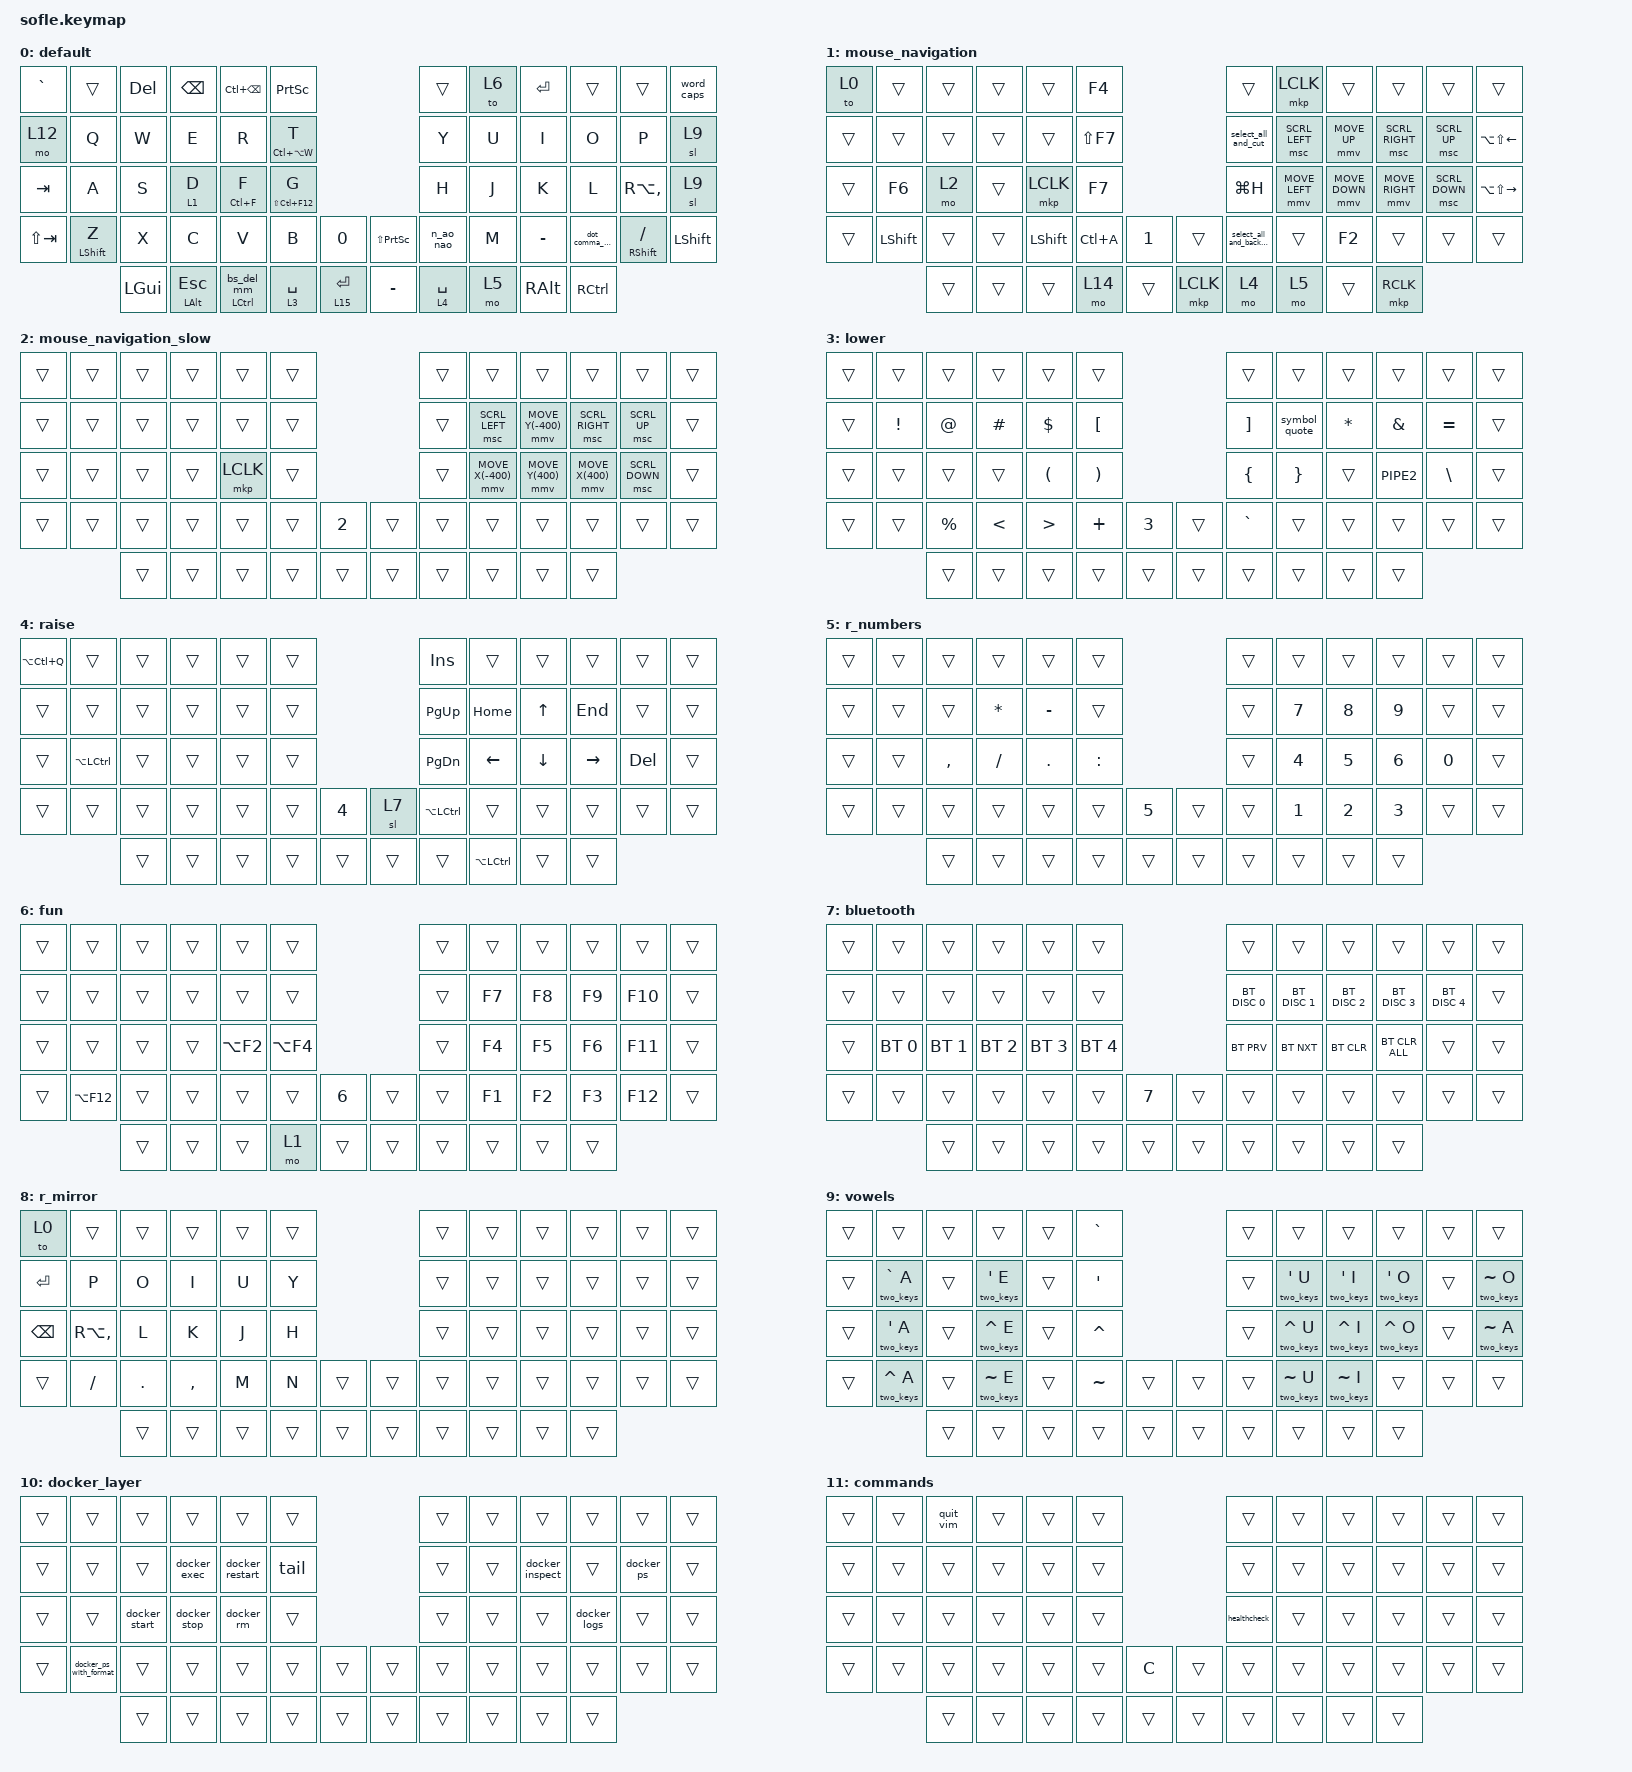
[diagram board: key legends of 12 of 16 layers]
/*
 * Copyright (c) 2020 The ZMK Contributors
 *
 * SPDX-License-Identifier: MIT
 */

#include <behaviors.dtsi>
#include <dt-bindings/zmk/bt.h>
#include <dt-bindings/zmk/keys.h>
#include <dt-bindings/zmk/pointing.h>

#define BASE 0
#define LOWER 1
#define RAISE 2
#define ADJUST 3
#define ZMK_POINTING_DEFAULT_MOVE_VAL 2000  // default: 600
#define ZMK_POINTING_DEFAULT_SCRL_VAL 20    // default: 10

/ {
    // Activate ADJUST layer by pressing raise and lower

    conditional_layers { compatible = "zmk,conditional-layers"; };

    combos {
        compatible = "zmk,combos";

        to_fun_layer {
            bindings = <&sl 6>;
            key-positions = <25 34>;
        };

        alt_x {
            bindings = <&kp LA(X)>;
            key-positions = <37 38>;
        };

        docker_layer {
            bindings = <&sl 10>;
            key-positions = <10 11>;
        };

        to_mirror_layer {
            bindings = <&to 8>;
            key-positions = <52 29>;
        };

        to_default_layer {
            bindings = <&to 0>;
            key-positions = <53 29>;
        };

        commands_layer {
            bindings = <&sl 11>;
            key-positions = <22 23>;
        };

        to_l_numbers {
            bindings = <&to 12>;
            key-positions = <0 1>;
        };

        to_mouse_layer_left {
            bindings = <&to 1>;
            key-positions = <55 30>;
        };

        to_wmctrl_layer {
            bindings = <&sl 13>;
            key-positions = <45 14>;
        };

        to_nav_layer {
            bindings = <&to 1>;
            key-positions = <25 48>;
        };

        colon {
            bindings = <&colon_scolon_mm>;
            key-positions = <31 19>;
        };

        comma {
            bindings = <&kp COMMA>;
            key-positions = <20 32>;
        };

        underscore {
            bindings = <&kp LS(UNDERSCORE)>;
            key-positions = <28 40>;
        };
    };

    macros {
        docker_exec: docker_exec {
            compatible = "zmk,behavior-macro";
            #binding-cells = <0>;
            bindings = <&kp D &kp O &kp C &kp K &kp E &kp R &kp SPACE &kp E &kp X &kp E &kp C &kp SPACE &kp MINUS &kp I &kp T &kp SPACE &kp SPACE &kp B &kp A &kp S &kp H &kp LC(LEFT_ARROW) &kp LEFT_ARROW>;
            label = "DOCKER_EXEC";
            wait-ms = <1>;
            tap-ms = <1>;
        };

        docker_logs: docker_logs {
            compatible = "zmk,behavior-macro";
            #binding-cells = <0>;
            bindings =
                <&kp D &kp O &kp C &kp K &kp E &kp R &kp SPACE &kp L &kp O &kp G &kp S &kp SPACE &kp MINUS &kp MINUS &kp T &kp A &kp I &kp L &kp SPACE &kp N1 &kp N0 &kp N0 &kp N0 &kp SPACE &kp MINUS &kp F &kp SPACE>,
                <&macro_press>;

            label = "DOCKER_LOGS";
            wait-ms = <1>;
            tap-ms = <1>;
        };

        docker_ps: docker_ps {
            compatible = "zmk,behavior-macro";
            #binding-cells = <0>;
            bindings = <&kp D &kp O &kp C &kp K &kp E &kp R &kp SPACE &kp P &kp S &kp SPACE &kp MINUS &kp A &kp SPACE &kp PIPE &kp SPACE &kp G &kp R &kp E &kp P &kp SPACE>;
            label = "DOCKER_PS";
            wait-ms = <1>;
            tap-ms = <1>;
        };

        docker_rm: docker_rm {
            compatible = "zmk,behavior-macro";
            #binding-cells = <0>;
            bindings = <&kp D &kp O &kp C &kp K &kp E &kp R &kp SPACE &kp R &kp M &kp SPACE &kp MINUS &kp F &kp SPACE>;
            label = "DOCKER_RM";
            wait-ms = <1>;
            tap-ms = <1>;
        };

        docker_start: docker_start {
            compatible = "zmk,behavior-macro";
            #binding-cells = <0>;
            bindings = <&kp D &kp O &kp C &kp K &kp E &kp R &kp SPACE &kp S &kp T &kp A &kp R &kp T &kp SPACE>;
            label = "DOCKER_START";
            wait-ms = <1>;
            tap-ms = <1>;
        };

        docker_stop: docker_stop {
            compatible = "zmk,behavior-macro";
            #binding-cells = <0>;
            bindings = <&kp D &kp O &kp C &kp K &kp E &kp R &kp SPACE &kp S &kp T &kp O &kp P &kp SPACE>;
            label = "DOCKER_STOP";
            wait-ms = <1>;
            tap-ms = <1>;
        };

        docker_inspect: docker_inspect {
            compatible = "zmk,behavior-macro";
            #binding-cells = <0>;
            bindings = <&kp D &kp O &kp C &kp K &kp E &kp R &kp SPACE &kp I &kp N &kp S &kp P &kp E &kp C &kp T &kp SPACE>;
            label = "DOCKER_INSPECT";
            wait-ms = <1>;
            tap-ms = <1>;
        };

        tail: tail {
            compatible = "zmk,behavior-macro";
            #binding-cells = <0>;
            bindings = <&kp T &kp A &kp I &kp L &kp SPACE &kp MINUS &kp F &kp SPACE &kp MINUS &kp N &kp SPACE &kp N1 &kp N0 &kp N0 &kp N0 &kp SPACE>;
            label = "TAIL";
            wait-ms = <1>;
            tap-ms = <1>;
        };

        docker_restart: docker_restart {
            compatible = "zmk,behavior-macro";
            #binding-cells = <0>;
            bindings = <&kp D &kp O &kp C &kp K &kp E &kp R &kp SPACE &kp R &kp E &kp S &kp T &kp A &kp R &kp T &kp SPACE>;
            label = "DOCKER_RESTART";
            wait-ms = <1>;
            tap-ms = <1>;
        };

        docker_ps_with_format: docker_ps_with_format {
            compatible = "zmk,behavior-macro";
            #binding-cells = <0>;
            bindings =
                <&macro_wait_time 100>,
                <&kp D &kp O &kp C &kp K &kp E &kp R &kp SPACE &kp P &kp S &kp SPACE &kp MINUS &kp MINUS &kp F &kp O &kp R &kp M &kp A &kp T &kp EQUAL &kp RA(DOUBLE_QUOTES) &kp T &kp A &kp B &kp L &kp E &kp SPACE &kp LBRC &kp LBRC &kp DOT &kp LS(I) &kp LS(D) &kp RBRC &kp RBRC &kp BSLH &kp T &kp LBRC &kp LBRC &kp DOT &kp LS(N) &kp A &kp M &kp E &kp S &kp RBRC &kp RBRC &kp BSLH &kp T &kp LBRC &kp LBRC &kp DOT &kp LS(S) &kp T &kp A &kp T &kp U &kp S &kp RBRC &kp RBRC &kp DQT>;

            label = "DOCKER_PS_WITH_FORMAT";
        };

        select_all_and_copy: select_all_and_copy {
            compatible = "zmk,behavior-macro";
            #binding-cells = <0>;
            bindings = <&kp LC(A) &kp LC(C)>;
            label = "SELECT_ALL_AND_COPY";
        };

        select_all_and_cut: select_all_and_cut {
            compatible = "zmk,behavior-macro";
            #binding-cells = <0>;
            bindings = <&kp LC(A) &kp LC(X)>;
            label = "SELECT_ALL_AND_CUT";
        };

        select_all_and_paste: select_all_and_paste {
            compatible = "zmk,behavior-macro";
            #binding-cells = <0>;
            bindings = <&kp LC(A) &kp LC(V)>;
            label = "SELECT_ALL_AND_PASTE";
        };

        healthcheck: healthcheck {
            compatible = "zmk,behavior-macro";
            #binding-cells = <0>;
            bindings = <&kp C &kp U &kp R &kp L &kp SPACE &kp L &kp O &kp C &kp A &kp L &kp H &kp O &kp S &kp T &kp COLON &kp N8 &kp N0 &kp N8 &kp N0 &kp FSLH &kp DLLR &kp A &kp P &kp P &kp FSLH &kp H &kp E &kp A &kp L &kp T &kp H &kp C &kp H &kp E &kp C &kp K &kp FSLH &kp I &kp N &kp F &kp O &kp HOME &kp A &kp P &kp P &kp EQUAL &kp SEMI &kp LEFT_ARROW>;
            label = "HEALTHCHECK";
            wait-ms = <1>;
            tap-ms = <1>;
        };

        select_all_and_backspace: select_all_and_backspace {
            compatible = "zmk,behavior-macro";
            #binding-cells = <0>;
            bindings = <&kp LC(A) &kp BACKSPACE>;
            label = "SELECT_ALL_AND_BACKSPACE";
        };

        wmctrl_coda: wmctrl_coda {
            compatible = "zmk,behavior-macro";
            #binding-cells = <0>;
            bindings =
                <&wmctrl>,
                <&macro_wait_time 1>,
                <&kp LS(C) &kp O &kp D &kp A &kp ENTER &kp ESC>;

            label = "WMCTRL_CODA";
            wait-ms = <0>;
            tap-ms = <0>;
        };

        wmctrl_gchat: wmctrl_gchat {
            compatible = "zmk,behavior-macro";
            #binding-cells = <0>;
            bindings =
                <&wmctrl>,
                <&macro_wait_time 1>,
                <&kp G &kp O &kp O &kp G &kp L &kp E &kp SPACE &kp C &kp H &kp A &kp T &kp ENTER &kp ESC>;

            label = "WMCTRL_GCHAT";
            wait-ms = <0>;
            tap-ms = <0>;
        };

        wmctrl: wmctrl {
            compatible = "zmk,behavior-macro";
            #binding-cells = <0>;
            bindings =
                <&kp LA(F2)>,
                <&macro_wait_time 1000>,
                <&kp BACKSPACE>,
                <&macro_wait_time 1>,
                <&kp W &kp M &kp C &kp T &kp R &kp L &kp SPACE &kp MINUS &kp A &kp SPACE &kp RA(DOUBLE_QUOTES) &kp RA(DOUBLE_QUOTES) &kp LEFT_ARROW>;

            label = "WMCTRL";
            wait-ms = <0>;
            tap-ms = <0>;
        };

        wmctrl_zgdevops: wmctrl_zgdevops {
            compatible = "zmk,behavior-macro";
            #binding-cells = <0>;
            bindings =
                <&wmctrl>,
                <&macro_wait_time 1>,
                <&kp MINUS &kp D &kp E &kp V &kp O &kp P &kp S &kp DOT &kp N3 &kp N0 &kp ENTER &kp ESC>;

            label = "WMCTRL_ZGDEVOPS";
        };

        wmctrl_zgdevops17: wmctrl_zgdevops17 {
            compatible = "zmk,behavior-macro";
            #binding-cells = <0>;
            bindings =
                <&wmctrl>,
                <&macro_wait_time 1>,
                <&kp MINUS &kp D &kp E &kp V &kp O &kp P &kp S &kp DOT &kp NUMBER_1 &kp NUMBER_7 &kp ENTER &kp ESC>;

            label = "WMCTRL_ZGDEVOPS17";
        };

        hold_alt: hold_alt {
            compatible = "zmk,behavior-macro";
            #binding-cells = <0>;
            bindings = <&kt LEFT_ALT &mo 1>;
            label = "HOLD_ALT";
        };

        two_keys: two_keys {
            compatible = "zmk,behavior-macro-two-param";
            #binding-cells = <2>;
            bindings = <&macro_param_1to1 &kp MACRO_PLACEHOLDER &macro_param_2to1 &kp MACRO_PLACEHOLDER>;
            label = "TWO_KEYS";
        };

        shift: shift {
            compatible = "zmk,behavior-macro-one-param";
            #binding-cells = <1>;
            bindings = <&macro_param_1to1 &kp MACRO_PLACEHOLDER>;
            label = "SHIFT";
        };

        nao: nao {
            compatible = "zmk,behavior-macro";
            #binding-cells = <0>;
            bindings = <&kp N &kp TILDE &kp A &kp O &kp SPACE>;
            label = "NAO";
            tap-ms = <0>;
            wait-ms = <0>;
        };

        ao: ao {
            compatible = "zmk,behavior-macro";
            #binding-cells = <0>;
            bindings = <&kp TILDE &kp A &kp O &kp SPACE>;
            label = "AO";
            wait-ms = <0>;
            tap-ms = <0>;
        };

        mouse_pointer: mouse_pointer {
            compatible = "zmk,behavior-macro";
            #binding-cells = <0>;
            bindings = <&to 1>, <&macro_wait_time 10>, <&sl 14>;

            label = "MOUSE_POINTER";
        };

        quit_vim: quit_vim {
            compatible = "zmk,behavior-macro";
            #binding-cells = <0>;
            bindings = <&kp ESC &kp COLON &kp Q &kp EXCL>;
            label = "QUIT_VIM";
        };
    };

    behaviors {
        mt_tap_preferred: mt_tap_preferred {
            compatible = "zmk,behavior-hold-tap";
            label = "MT_TAP_PREFERRED";
            bindings = <&kp>, <&kp>;

            #binding-cells = <2>;
            flavor = "tap-preferred";
            tapping-term-ms = <250>;
        };

        symbol_bracket: symbol_bracket {
            compatible = "zmk,behavior-mod-morph";
            label = "SYMBOL_BRACKET";
            bindings = <&kp LEFT_BRACKET>, <&kp RIGHT_BRACKET>;

            #binding-cells = <0>;
            mods = <(MOD_LSFT|MOD_LCTL)>;
        };

        symbol_brace: symbol_brace {
            compatible = "zmk,behavior-mod-morph";
            label = "SYMBOL_BRACE";
            bindings = <&kp LEFT_BRACE>, <&kp RIGHT_BRACE>;

            #binding-cells = <0>;
            mods = <(MOD_LCTL|MOD_LSFT)>;
        };

        symbol_quote: symbol_quote {
            compatible = "zmk,behavior-mod-morph";
            label = "SYMBOL_QUOTE";
            bindings = <&kp RA(SINGLE_QUOTE)>, <&kp RA(DOUBLE_QUOTES)>;

            #binding-cells = <0>;
            mods = <(MOD_LCTL|MOD_LSFT)>;
        };

        symbol_colon: symbol_colon {
            compatible = "zmk,behavior-mod-morph";
            label = "SYMBOL_COLON";
            bindings = <&kp SEMICOLON>, <&kp COLON>;

            #binding-cells = <0>;
            mods = <(MOD_LCTL|MOD_LSFT)>;
        };

        symbol_slash: symbol_slash {
            compatible = "zmk,behavior-mod-morph";
            label = "SYMBOL_SLASH";
            bindings = <&kp SLASH>, <&kp BACKSLASH>;

            #binding-cells = <0>;
            mods = <(MOD_LSFT|MOD_RSFT)>;
        };

        symbol_parenthesis: symbol_parenthesis {
            compatible = "zmk,behavior-mod-morph";
            label = "SYMBOL_PARENTHESIS";
            bindings = <&kp LEFT_PARENTHESIS>, <&kp RIGHT_PARENTHESIS>;

            #binding-cells = <0>;
            mods = <(MOD_LCTL|MOD_LSFT)>;
        };

        bs_del_mm: bs_del_mm {
            compatible = "zmk,behavior-mod-morph";
            label = "BS_DEL_MM";
            bindings = <&kp BACKSPACE>, <&kp DELETE>;

            #binding-cells = <0>;
            mods = <(MOD_LSFT)>;
        };

        bs_del_ctrl_ht: bs_del_ctrl_ht {
            compatible = "zmk,behavior-hold-tap";
            label = "BS_DEL_CTRL_HT";
            bindings = <&kp>, <&bs_del_mm>;

            #binding-cells = <2>;
            tapping-term-ms = <200>;
        };

        colon_scolon_mm: colon_scolon_mm {
            compatible = "zmk,behavior-mod-morph";
            label = "COLON_SCOLON_MM";
            bindings = <&kp SEMICOLON>, <&kp COLON>;

            #binding-cells = <0>;
            mods = <(MOD_LSFT|MOD_RSFT)>;
        };

        dot_comma_mm: dot_comma_mm {
            compatible = "zmk,behavior-mod-morph";
            label = "DOT_COMMA_MM";
            bindings = <&kp DOT>, <&kp COMMA>;

            #binding-cells = <0>;
            mods = <(MOD_LSFT|MOD_RSFT)>;
        };

        n_ao_nao: n_ao_nao {
            compatible = "zmk,behavior-tap-dance";
            label = "N_AO_NAO";
            #binding-cells = <0>;
            bindings = <&kp N>, <&ao>, <&nao>;
        };

        ced_vowels_td: ced_vowels_td {
            compatible = "zmk,behavior-tap-dance";
            label = "CED_VOWELS_TD";
            #binding-cells = <0>;
            bindings = <&sl 9>, <&kp RA(COMMA)>;
        };

        ht_mouse_pointer: ht_mouse_pointer {
            compatible = "zmk,behavior-hold-tap";
            label = "HT_MOUSE_POINTER";
            bindings = <&mouse_pointer>, <&kp>;

            #binding-cells = <2>;
            tapping-term-ms = <200>;
            flavor = "tap-preferred";
        };

        kp_to: kp_to {
            compatible = "zmk,behavior-hold-tap";
            label = "KP_TO";
            bindings = <&to>, <&kp>;

            #binding-cells = <2>;
            tapping-term-ms = <200>;
            flavor = "tap-preferred";
        };

        mt_tap_unless_interruped: mt_tap_unless_interruped {
            compatible = "zmk,behavior-hold-tap";
            label = "MT_TAP_UNLESS_INTERRUPED";
            bindings = <&kp>, <&kp>;

            #binding-cells = <2>;
            flavor = "tap-unless-interrupted";
            tapping-term-ms = <250>;
        };

        mt_hold_prefered: mt_hold_prefered {
            compatible = "zmk,behavior-hold-tap";
            label = "MT_HOLD_PREFERED";
            bindings = <&kp>, <&kp>;

            #binding-cells = <2>;
            flavor = "hold-preferred";
            tapping-term-ms = <250>;
        };

        word_caps: word_caps {
            compatible = "zmk,behavior-mod-morph";
            label = "WORD_CAPS";
            bindings = <&caps_word>, <&kp CAPSLOCK>;

            #binding-cells = <0>;
            mods = <(MOD_LCTL)>;
        };
    };

    keymap {
        compatible = "zmk,keymap";

        default_layer {
            display-name = "default";

            // ------------------------------------------------------------------------------------------------------------
            // |   `   |  1  |  2  |  3   |  4   |  5   |                   |  6   |  7    |  8    |  9   |   0   |       |
            // |  ESC  |  Q  |  W  |  E   |  R   |  T   |                   |  Y   |  U    |  I    |  O   |   P   | BKSPC |
            // |  TAB  |  A  |  S  |  D   |  F   |  G   |                   |  H   |  J    |  K    |  L   |   ;   |   '   |
            // | SHIFT |  Z  |  X  |  C   |  V   |  B   |  MUTE  |  |       |  N   |  M    |  ,    |  .   |   /   | SHIFT |
            //               | GUI | ALT  | CTRL | LOWER|  ENTER |  | SPACE | RAISE| CTRL  | ALT   | GUI  |

            bindings = <
&kp GRAVE    &trans                          &kp DELETE  &kp BACKSPACE  &kp LC(BACKSPACE)          &kp PRINTSCREEN                                                       &trans       &to 6  &kp ENTER      &trans             &trans                               &word_caps
&mo 12       &kp Q                           &kp W       &kp E          &kp R                      &mt_tap_preferred LC(LA(W)) T                                         &kp Y        &kp U  &kp I          &kp O              &kp P                                &sl 9
&kp TAB      &kp A                           &kp S       &lt 1 D        &mt_tap_preferred LC(F) F  &mt_tap_preferred LS(LC(F12)) G                                       &kp H        &kp J  &kp K          &kp L              &kp RA(COMMA)                        &sl 9
&kp LS(TAB)  &mt_hold_prefered LEFT_SHIFT Z  &kp X       &kp C          &kp V                      &kp B                            &kp NUMBER_0    &kp LS(PRINTSCREEN)  &n_ao_nao    &kp M  &kp MINUS      &dot_comma_mm      &mt_hold_prefered RIGHT_SHIFT SLASH  &kp LEFT_SHIFT
                                             &kp LGUI    &mt LALT ESC   &bs_del_ctrl_ht LCTRL 0    &lt 3 SPACE                      &lt 15 ENTER    &kp MINUS            &lt 4 SPACE  &mo 5  &kp RIGHT_ALT  &kp RIGHT_CONTROL
            >;

            sensor-bindings =
                <&inc_dec_kp C_VOL_DN C_VOL_UP>,
                <&inc_dec_kp LG(LS(GREATER_THAN)) LS(LG(LESS_THAN))>;
        };

        mouse_navigation {
            bindings = <
&to 0   &trans          &trans  &trans  &trans          &kp F4                           &trans                     &mkp LCLK       &trans          &trans           &trans          &trans
&trans  &trans          &trans  &trans  &trans          &kp LS(F7)                       &select_all_and_cut        &msc SCRL_LEFT  &mmv MOVE_UP    &msc SCRL_RIGHT  &msc SCRL_UP    &kp LA(LS(LEFT))
&trans  &kp F6          &mo 2   &trans  &mkp LCLK       &kp F7                           &kp LG(H)                  &mmv MOVE_LEFT  &mmv MOVE_DOWN  &mmv MOVE_RIGHT  &msc SCRL_DOWN  &kp LA(LS(RIGHT))
&trans  &kp LEFT_SHIFT  &trans  &trans  &kp LEFT_SHIFT  &kp LC(A)   &kp N1    &trans     &select_all_and_backspace  &trans          &kp F2          &trans           &trans          &trans
                        &trans  &trans  &trans          &mo 14      &trans    &mkp LCLK  &mo 4                      &mo 5           &trans          &mkp RCLK
            >;
        };

        mouse_navigation_slow {
            bindings = <
&trans  &trans  &trans  &trans  &trans     &trans                    &trans  &trans             &trans             &trans            &trans          &trans
&trans  &trans  &trans  &trans  &trans     &trans                    &trans  &msc SCRL_LEFT     &mmv MOVE_Y(-400)  &msc SCRL_RIGHT   &msc SCRL_UP    &trans
&trans  &trans  &trans  &trans  &mkp LCLK  &trans                    &trans  &mmv MOVE_X(-400)  &mmv MOVE_Y(400)   &mmv MOVE_X(400)  &msc SCRL_DOWN  &trans
&trans  &trans  &trans  &trans  &trans     &trans  &kp N2    &trans  &trans  &trans             &trans             &trans            &trans          &trans
                &trans  &trans  &trans     &trans  &trans    &trans  &trans  &trans             &trans             &trans
            >;
        };

        symbols {
            display-name = "lower";

            // TODO: Some binds are waiting for shifted keycode support.
            // ------------------------------------------------------------------------------------------------------------
            // |       |  F1 |  F2 |  F3  |  F4  |  F5  |                   |  F6  |  F7   |  F8   |  F9  |  F10  |  F11  |
            // |   `   |  1  |  2  |  3   |  4   |  5   |                   |  6   |  7    |  8    |  9   |   0   |  F12  |
            // |       |  !  |  @  |  #   |  $   |  %   |                   |  ^   |  &    |  *    |  (   |   )   |   |   |
            // |       |  =  |  -  |  +   |  {   |  }   |        |  |       |  [   |  ]    |  ;    |  :   |   \   |       |
            //               |     |      |      |      |        |  |       |      |       |       |      |

            bindings = <
&trans  &trans           &trans       &trans         &trans                &trans                                   &trans             &trans           &trans        &trans         &trans         &trans
&trans  &kp EXCLAMATION  &kp AT_SIGN  &kp HASH       &kp DOLLAR            &kp LEFT_BRACKET                         &kp RIGHT_BRACKET  &symbol_quote    &kp ASTERISK  &kp AMPERSAND  &kp EQUAL      &trans
&trans  &trans           &trans       &trans         &kp LEFT_PARENTHESIS  &kp RIGHT_PARENTHESIS                    &kp LEFT_BRACE     &kp RIGHT_BRACE  &trans        &kp PIPE2      &kp BACKSLASH  &trans
&trans  &trans           &kp PERCENT  &kp LESS_THAN  &kp GREATER_THAN      &kp PLUS               &kp N3    &trans  &kp GRAVE          &trans           &trans        &trans         &trans         &trans
                         &trans       &trans         &trans                &trans                 &trans    &trans  &trans             &trans           &trans        &trans
            >;

            sensor-bindings = <&inc_dec_kp C_VOL_UP C_VOL_DN &inc_dec_kp PG_UP PG_DN>;
        };

        nav {
            display-name = "raise";

            // ------------------------------------------------------------------------------------------------------------
            // | BTCLR | BT1  | BT2  |  BT3  |  BT4  |  BT5 |                |      |      |       |      |       |       |
            // |       | INS  | PSCR | GUI   |       |      |                | PGUP |      |   ^   |      |       |       |
            // |       | ALT  | CTRL | SHIFT |       | CAPS |                | PGDN |   <- |   v   |  ->  |  DEL  | BKSPC |
            // |       | UNDO | CUT  | COPY  | PASTE |      |      |  |      |      |      |       |      |       |       |
            //                |      |       |       |      |      |  |      |      |      |       |      |

            bindings = <
&kp LA(LC(Q))  &trans         &trans  &trans  &trans  &trans                    &kp INS        &trans                &trans          &trans     &trans      &trans
&trans         &trans         &trans  &trans  &trans  &trans                    &kp PG_UP      &kp HOME              &kp UP_ARROW    &kp END    &trans      &trans
&trans         &kp LA(LCTRL)  &trans  &trans  &trans  &trans                    &kp PAGE_DOWN  &kp LEFT_ARROW        &kp DOWN_ARROW  &kp RIGHT  &kp DELETE  &trans
&trans         &trans         &trans  &trans  &trans  &trans  &kp N4    &sl 7   &kp LA(LCTRL)  &trans                &trans          &trans     &trans      &trans
                              &trans  &trans  &trans  &trans  &trans    &trans  &trans         &kp LA(LEFT_CONTROL)  &trans          &trans
            >;

            sensor-bindings = <&inc_dec_kp C_VOL_UP C_VOL_DN &inc_dec_kp PG_UP PG_DN>;
        };

        r_numbers {
            bindings = <
&trans  &trans  &trans     &trans        &trans      &trans                       &trans  &trans  &trans        &trans  &trans  &trans
&trans  &trans  &trans     &kp ASTERISK  &kp MINUS   &trans                       &trans  &kp N7  &kp N8        &kp N9  &trans  &trans
&trans  &trans  &kp COMMA  &kp SLASH     &kp PERIOD  &kp COLON                    &trans  &kp N4  &kp NUMBER_5  &kp N6  &kp N0  &trans
&trans  &trans  &trans     &trans        &trans      &trans     &kp N5    &trans  &trans  &kp N1  &kp N2        &kp N3  &trans  &trans
                &trans     &trans        &trans      &trans     &trans    &trans  &trans  &trans  &trans        &trans
            >;
        };

        fun {
            bindings = <
&trans  &trans       &trans  &trans  &trans      &trans                        &trans  &trans  &trans  &trans  &trans   &trans
&trans  &trans       &trans  &trans  &trans      &trans                        &trans  &kp F7  &kp F8  &kp F9  &kp F10  &trans
&trans  &trans       &trans  &trans  &kp LA(F2)  &kp LA(F4)                    &trans  &kp F4  &kp F5  &kp F6  &kp F11  &trans
&trans  &kp LA(F12)  &trans  &trans  &trans      &trans      &kp N6    &trans  &trans  &kp F1  &kp F2  &kp F3  &kp F12  &trans
                     &trans  &trans  &trans      &mo 1       &trans    &trans  &trans  &trans  &trans  &trans
            >;
        };

        bluetooth {
            bindings = <
&trans  &trans        &trans        &trans        &trans        &trans                          &trans         &trans         &trans         &trans          &trans         &trans
&trans  &trans        &trans        &trans        &trans        &trans                          &bt BT_DISC 0  &bt BT_DISC 1  &bt BT_DISC 2  &bt BT_DISC 3   &bt BT_DISC 4  &trans
&trans  &bt BT_SEL 0  &bt BT_SEL 1  &bt BT_SEL 2  &bt BT_SEL 3  &bt BT_SEL 4                    &bt BT_PRV     &bt BT_NXT     &bt BT_CLR     &bt BT_CLR_ALL  &trans         &trans
&trans  &trans        &trans        &trans        &trans        &trans        &kp N7    &trans  &trans         &trans         &trans         &trans          &trans         &trans
                      &trans        &trans        &trans        &trans        &trans    &trans  &trans         &trans         &trans         &trans
            >;
        };

        r_mirror {
            bindings = <
&to 0          &trans         &trans   &trans     &trans  &trans                    &trans  &trans  &trans  &trans  &trans  &trans
&kp ENTER      &kp P          &kp O    &kp I      &kp U   &kp Y                     &trans  &trans  &trans  &trans  &trans  &trans
&kp BACKSPACE  &kp RA(COMMA)  &kp L    &kp K      &kp J   &kp H                     &trans  &trans  &trans  &trans  &trans  &trans
&trans         &kp SLASH      &kp DOT  &kp COMMA  &kp M   &kp N   &trans    &trans  &trans  &trans  &trans  &trans  &trans  &trans
                              &trans   &trans     &trans  &trans  &trans    &trans  &trans  &trans  &trans  &trans
            >;
        };

        vowels {
            bindings = <
&trans  &trans                  &trans  &trans                  &trans  &kp GRAVE                         &trans  &trans                    &trans                    &trans                    &trans  &trans
&trans  &two_keys GRAVE A       &trans  &two_keys APOSTROPHE E  &trans  &kp APOSTROPHE                    &trans  &two_keys SINGLE_QUOTE U  &two_keys SINGLE_QUOTE I  &two_keys SINGLE_QUOTE O  &trans  &two_keys TILDE O
&trans  &two_keys APOSTROPHE A  &trans  &two_keys CARET E       &trans  &kp CARET                         &trans  &two_keys CARET U         &two_keys CARET I         &two_keys CARET O         &trans  &two_keys TILDE A
&trans  &two_keys CARET A       &trans  &two_keys TILDE E       &trans  &kp TILDE       &trans    &trans  &trans  &two_keys TILDE U         &two_keys TILDE I         &trans                    &trans  &trans
                                &trans  &trans                  &trans  &trans          &trans    &trans  &trans  &trans                    &trans                    &trans
            >;
        };

        docker_layer {
            bindings = <
&trans  &trans                  &trans         &trans        &trans           &trans                    &trans  &trans  &trans           &trans        &trans      &trans
&trans  &trans                  &trans         &docker_exec  &docker_restart  &tail                     &trans  &trans  &docker_inspect  &trans        &docker_ps  &trans
&trans  &trans                  &docker_start  &docker_stop  &docker_rm       &trans                    &trans  &trans  &trans           &docker_logs  &trans      &trans
&trans  &docker_ps_with_format  &trans         &trans        &trans           &trans  &trans    &trans  &trans  &trans  &trans           &trans        &trans      &trans
                                &trans         &trans        &trans           &trans  &trans    &trans  &trans  &trans  &trans           &trans
            >;
        };

        commands {
            bindings = <
&trans  &trans  &quit_vim  &trans  &trans  &trans                    &trans        &trans  &trans  &trans  &trans  &trans
&trans  &trans  &trans     &trans  &trans  &trans                    &trans        &trans  &trans  &trans  &trans  &trans
&trans  &trans  &trans     &trans  &trans  &trans                    &healthcheck  &trans  &trans  &trans  &trans  &trans
&trans  &trans  &trans     &trans  &trans  &trans  &kp C     &trans  &trans        &trans  &trans  &trans  &trans  &trans
                &trans     &trans  &trans  &trans  &trans    &trans  &trans        &trans  &trans  &trans
            >;
        };

        l_numbers {
            bindings = <
&to 0   &trans  &trans              &trans              &trans            &trans                                &trans  &trans  &trans  &trans  &trans  &trans
&trans  &trans  &kp NUMBER_7        &kp NUMBER_8        &kp NUMBER_9      &trans                                &trans  &trans  &trans  &trans  &trans  &trans
&trans  &trans  &mt COMMA NUMBER_4  &mt SLASH NUMBER_5  &mt DOT NUMBER_6  &kp COLON                             &trans  &trans  &trans  &trans  &trans  &trans
&trans  &trans  &kp NUMBER_1        &kp NUMBER_2        &kp NUMBER_3      &mt NUMBER_0 UNDER  &trans    &trans  &trans  &trans  &trans  &trans  &trans  &trans
                &trans              &trans              &trans            &trans              &trans    &trans  &trans  &trans  &trans  &trans
            >;
        };

        wmctrl {
            bindings = <
&trans  &wmctrl_zgdevops  &wmctrl_zgdevops17  &trans        &trans  &trans                           &trans  &trans  &trans  &trans  &trans  &trans
&trans  &trans            &trans              &trans        &trans  &trans                           &trans  &trans  &trans  &trans  &trans  &trans
&trans  &trans            &trans              &trans        &trans  &wmctrl_gchat                    &trans  &trans  &trans  &trans  &trans  &trans
&trans  &trans            &trans              &wmctrl_coda  &trans  &trans         &kp W     &trans  &trans  &trans  &trans  &trans  &trans  &trans
                          &trans              &trans        &trans  &trans         &trans    &trans  &trans  &trans  &trans  &trans
            >;
        };

        mouse_points {
            bindings = <
&trans           &trans       &trans       &trans       &trans       &trans                             &trans           &trans   &trans       &trans       &trans           &trans
&kp RS(RG(F14))  &kp RS(F14)  &kp RG(F14)  &kp RC(F14)  &kp RA(F14)  &kp RS(RA(F14))                    &kp LS(LA(F14))  &kp F14  &kp LC(F14)  &kp LA(F14)  &kp LA(LC(F14))  &kp LG(LC(F14))
&trans           &trans       &trans       &trans       &trans       &trans                             &kp LS(LA(F15))  &kp F15  &kp LC(F15)  &kp LA(F15)  &kp LA(LC(F15))  &kp LC(LG(F15))
&trans           &trans       &trans       &trans       &trans       &trans           &trans    &trans  &kp LS(LA(F16))  &kp F16  &kp LC(F16)  &kp LA(F16)  &kp LC(LA(F16))  &kp LC(LG(F16))
                              &trans       &trans       &trans       &trans           &trans    &trans  &trans           &trans   &trans       &trans
            >;
        };

        nav_left {
            bindings = <
&to 0   &trans  &trans    &kp ENTER     &trans     &kp INSERT                       &trans  &trans  &trans  &trans  &trans  &trans
&trans  &trans  &kp HOME  &kp UP_ARROW  &kp END    &kp PAGE_UP                      &trans  &trans  &trans  &trans  &trans  &trans
&trans  &mo 12  &kp LEFT  &kp DOWN      &kp RIGHT  &kp PAGE_DOWN                    &trans  &trans  &trans  &trans  &trans  &trans
&trans  &trans  &trans    &trans        &trans     &trans         &trans    &trans  &trans  &trans  &trans  &trans  &trans  &trans
                &trans    &trans        &trans     &trans         &trans    &trans  &trans  &trans  &trans  &trans
            >;
        };
    };
};
